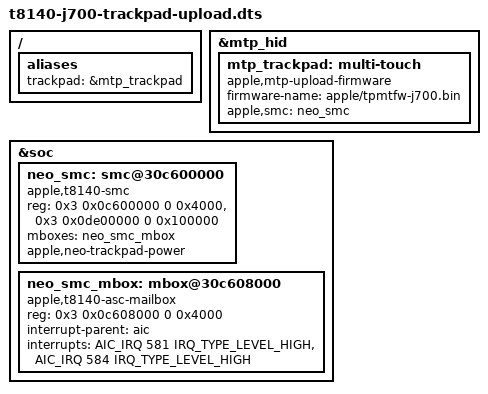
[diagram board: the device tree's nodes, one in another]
// SPDX-License-Identifier: GPL-2.0+ OR MIT
/* J700 firmware upload and verified SMC power sequence experiment.
 * Keep the exact working keyboard tree; add only the reviewed SMC resources
 * and explicitly opted-in trackpad. No SMC battery/notification children.
 */
#include "t8140-j700-input.dts"

/ {
	aliases {
		trackpad = &mtp_trackpad;
	};
};

&mtp_hid {
	mtp_trackpad: multi-touch {
		apple,mtp-upload-firmware;
		firmware-name = "apple/tpmtfw-j700.bin";
		apple,smc = <&neo_smc>;
	};
};

&soc {
	neo_smc: smc@30c600000 {
		compatible = "apple,t8140-smc";
		reg = <0x3 0x0c600000 0 0x4000>,
		      <0x3 0x0de00000 0 0x100000>;
		reg-names = "smc", "sram";
		mboxes = <&neo_smc_mbox>;
		apple,neo-trackpad-power;
		/* Explicit new IDs preserve every working keyboard phandle. */
		phandle = <0x80>;
	};

	neo_smc_mbox: mbox@30c608000 {
		compatible = "apple,t8140-asc-mailbox", "apple,asc-mailbox-v4";
		reg = <0x3 0x0c608000 0 0x4000>;
		interrupt-parent = <&aic>;
		interrupts = <AIC_IRQ 581 IRQ_TYPE_LEVEL_HIGH>,
		             <AIC_IRQ 584 IRQ_TYPE_LEVEL_HIGH>;
		interrupt-names = "send-empty", "recv-not-empty";
		#mbox-cells = <0>;
		phandle = <0x81>;
	};
};
